# MEC1322 register map
Vendor: Microchip Technology Inc.; Series: ARMCM4F; File version: 1.0
CPU: CM4 r1p0, little endian, MPU, FPU, 3 interrupt priority bits
Registers are 32-bit, read-write, reset 0x0 unless marked. A register's access mark holds for its fields unless they carry their own. Offsets are from the block's base; [hi:lo] are bit positions; lines under a group give offsets from that group; {n}, {i} and the like mark numbered series.

## LED — The blinking/breathing hardware is implemented using a PWM. The PWM can be driven either by the 48 MHz clock or by a 32.768 KHz clock input. When driven by the 48 MHz clock, the PWM can be used as a standard 8-bit PWM in order to control a fan. When used to drive blinking or breathing LEDs, the 32.768 KHz clock source is used.
Base 0x4000B800
{0x0+0x100*i} CH[{i}] (i=0..3) group — Channel implemented will have these registers to determine that channel's operation.
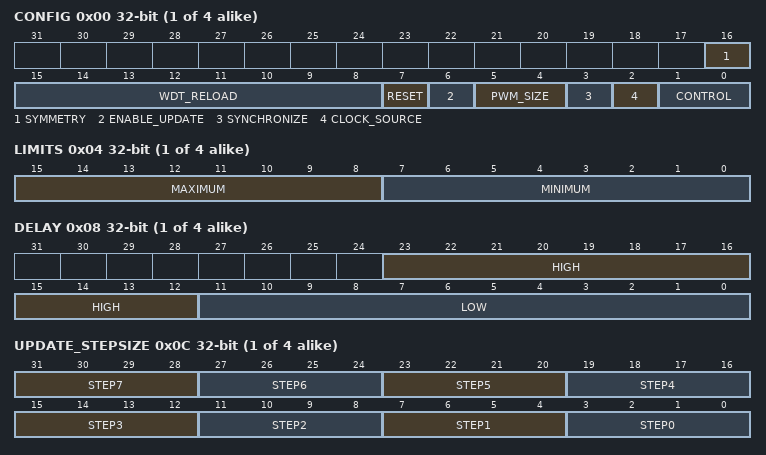
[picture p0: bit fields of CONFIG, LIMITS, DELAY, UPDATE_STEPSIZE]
  0x00 CONFIG — LED Configuration
    [16] SYMMETRY — SYMMETRY 1=The rising and falling ramp times are in Asymmetric mode. 0=The rising and falling ramp times are in Symmetric mode.
    [15:8] WDT_RELOAD — WDT_RELOAD The PWM Watchdog Timer counter reload value. On system reset, it defaults to 14h, which corresponds to a 4 second Watchdog timeout value.
    [7] RESET write — RESET Writes of '1' to this bit resets the PWM registers to their default values. This bit is self clearing. Writes of '0' to this bit have no effect.
    [6] ENABLE_UPDATE — ENABLE_UPDATE This bit is set to 1 when written with a '1'. Writes of '0' have no effect. Hardware clears this bit to 0 when the breathing configuration registers are updated at the end of a PWM period. The current state of the bit is readable any time.
    [5:4] PWM_SIZE — PWM_SIZE This bit controls the behavior of PWM: 3=Reserved. 2=PWM is configured as a 6-bit PWM. 1=PWM is configured as a 7-bit PWM. 0=PWM is configured as an 8-bit PWM
    [3] SYNCHRONIZE — SYNCHRONIZE When this bit is '1', all counters for all LEDs are reset to their initial values. When this bit is '0' in the LED Configuration Register for all LEDs, then all counters for LEDs that are configured to blink or breathe will increment or decrement, as required.
    [2] CLOCK_SOURCE — 1=Clock source is the 48 MHz clock, 0=Clock source is the 32.768 KHz clock
    [1:0] CONTROL — CONTROL 3=PWM is always on. 2=LED blinking (standard PWM). 1=LED breathing configuration. 0=PWM is always off. All internal registers and counters are reset to 0. Clocks are gated
  0x04 LIMITS — LED Limits This register may be written at any time. Values written into the register are held in an holding register, which is transferred into the actual register at the end of a PWM period. The two byte fields may be written independently. Reads of this register return the current contents and not the value of the holding register.
    [15:8] MAXIMUM — In breathing mode, when the current duty cycle is greater than or equal to this value the breathing apparatus holds the current duty cycle for the period specified by the field HD in register LED_DELAY, then starts decrementing the current duty cycle
    [7:0] MINIMUM — In breathing mode, when the current duty cycle is less than or equal to this value the breathing apparatus holds the current duty cycle for the period specified by the field LD in register LED_DELAY, then starts incrementing the current duty cycle In blinking mode, this field defines the duty cycle of the blink function.
  0x08 DELAY — LED Delay
    [23:12] HIGH — In breathing mode, the number of PWM periods to wait before updating the current duty cycle when the current duty cycle is greater than or equal to the value MAX in register LED_LIMIT.
    [11:0] LOW — The number of PWM periods to wait before updating the current duty cycle when the current duty cycle is greater than or equal to the value MIN in register LED_LIMIT.
  0x0C UPDATE_STEPSIZE — This register has eight segment fields which provide the amount the current duty cycle is adjusted at the end of every PWM period. Segment field selection is decoded based on the segment index. The segment index equation utilized depends on the SYMMETRY bit in the LED Configuration Register Register) . In Symmetric Mode the Segment_Index[2:0] = Duty Cycle Bits[7:5] . In Asymmetric Mode the Segment_Index[2:0] is the bit concatenation of following: Segment_Index[2] = (FALLING RAMP TIME in Figure 30-3, "Clipping Example") and Segment_Index[1:0] = Duty Cycle Bits[7:6].
    [31:28] STEP7 — Amount the current duty cycle is adjusted at the end of every PWM period when the segment index is equal to 111.
    [27:24] STEP6 — Amount the current duty cycle is adjusted at the end of every PWM period when the segment index is equal to 110.
    [23:20] STEP5 — Amount the current duty cycle is adjusted at the end of every PWM period when the segment index is equal to 101
    [19:16] STEP4 — Amount the current duty cycle is adjusted at the end of every PWM period when the segment index is equal to 100.
    [15:12] STEP3 — Amount the current duty cycle is adjusted at the end of every PWM period when the segment index is equal to 011.
    [11:8] STEP2 — Amount the current duty cycle is adjusted at the end of every PWM period when the segment index is equal to 010.
    [7:4] STEP1 — Amount the current duty cycle is adjusted at the end of every PWM period when the segment index is equal to 001.
    [3:0] STEP0 — Amount the current duty cycle is adjusted at the end of every PWM period when the segment index is equal to 000.
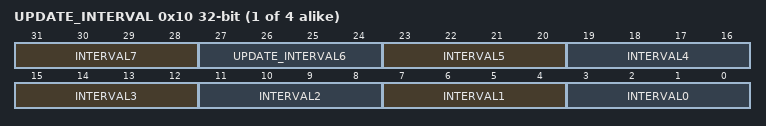
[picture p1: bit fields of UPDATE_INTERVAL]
  0x10 UPDATE_INTERVAL — LED Update Interval
    [31:28] INTERVAL7 — The number of PWM periods between updates to current duty cycle when the segment index is equal to 111b.
    [27:24] UPDATE_INTERVAL6 — The number of PWM periods between updates to current duty cycle when the segment index is equal to 110b.
    [23:20] INTERVAL5 — The number of PWM periods between updates to current duty cycle when the segment index is equal to 101b.
    [19:16] INTERVAL4 — The number of PWM periods between updates to current duty cycle when the segment index is equal to 100b.
    [15:12] INTERVAL3 — The number of PWM periods between updates to current duty cycle when the segment index is equal to 011b.
    [11:8] INTERVAL2 — The number of PWM periods between updates to current duty cycle when the segment index is equal to 010b.
    [7:4] INTERVAL1 — The number of PWM periods between updates to current duty cycle when the segment index is equal to 001b.
    [3:0] INTERVAL0 — The number of PWM periods between updates to current duty cycle when the segment index is equal to 000b.
